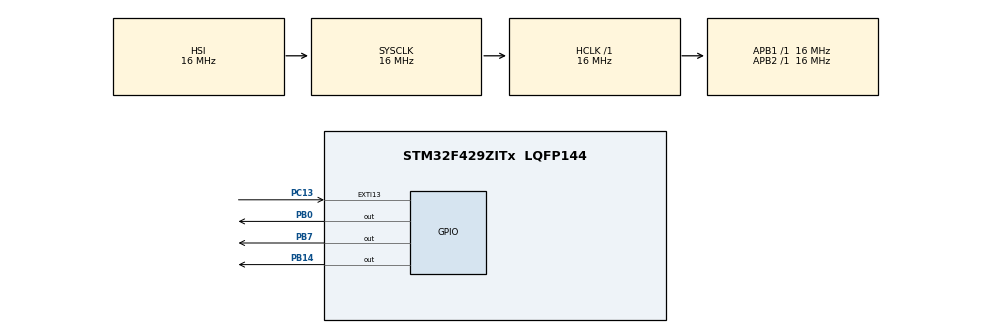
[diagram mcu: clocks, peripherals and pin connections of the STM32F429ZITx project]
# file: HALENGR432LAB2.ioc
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Mcu.Family=STM32F4
Mcu.Name=STM32F429ZITx
Mcu.Package=LQFP144
NVIC.EXTI15_10_IRQn=true\:0\:0\:false\:false\:true\:true\:true\:true
NVIC.PriorityGroup=NVIC_PRIORITYGROUP_4
NVIC.TIM2_IRQn=true\:0\:0\:false\:false\:true\:true\:true\:true
PB0.Signal=GPIO_Output
PB14.Signal=GPIO_Output
PB7.Signal=GPIO_Output
PC13.Signal=GPXTI13
ProjectManager.HeapSize=0x200
ProjectManager.StackSize=0x400
ProjectManager.TargetToolchain=MDK-ARM V5
RCC.AHBFreq_Value=16000000
RCC.APB1Freq_Value=16000000
RCC.APB2Freq_Value=16000000
RCC.CortexFreq_Value=16000000
RCC.HSE_VALUE=25000000
RCC.HSI_VALUE=16000000
RCC.LSE_VALUE=32768
RCC.SYSCLKFreq_VALUE=16000000
RCC.VCOOutputFreq_Value=192000000
TIM2.Period=21000
TIM2.Prescaler=999
VP_TIM2_VS_ClockSourceINT.Mode=Internal
board=custom

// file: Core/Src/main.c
/* USER CODE BEGIN Header */
/**
  ******************************************************************************
  * @file           : main.c
  * @brief          : Main program body
  ******************************************************************************
  * @attention
  *
  * Copyright (c) 2024 STMicroelectronics.
  * All rights reserved.
  *
  * This software is licensed under terms that can be found in the LICENSE file
  * in the root directory of this software component.
  * If no LICENSE file comes with this software, it is provided AS-IS.
  *
  ******************************************************************************
  */
/* USER CODE END Header */
#include "main.h"

/* USER CODE BEGIN PD */
int count = 0;

int Countup = 1;
int Downcount_Delay = 0;
int Bit0 = 0; // bit 1 2 & 3 for out binary counter
int Bit1 = 0; // you could say it's a BIT of a hacky solution
int Bit2 = 0; // yea ...
/* USER CODE END PD */

TIM_HandleTypeDef htim2;

void SystemClock_Config(void);
static void MX_GPIO_Init(void);
static void MX_TIM2_Init(void);

int main(void)
{

  /* MCU Configuration--------------------------------------------------------*/

  /* Reset of all peripherals, Initializes the Flash interface and the Systick. */
  HAL_Init();

  /* Configure the system clock */
  SystemClock_Config();

  /* Initialize all configured peripherals */
  MX_GPIO_Init();
  MX_TIM2_Init();
  /* USER CODE BEGIN 2 */

/*
void HAL_GPIO_EXTI_Callback()// callback for pushbutton
{

}
	*/

/* USER CODE END 2 */

  /* Infinite loop */
  while (1)
  {
while(1) {

	/*
HAL_GPIO_TogglePin(GPIOB, GPIO_PIN_0);
HAL_GPIO_TogglePin(GPIOB, GPIO_PIN_7);
HAL_GPIO_TogglePin(GPIOB, GPIO_PIN_14);

	HAL_GPIO_WritePin(GPIOB, GPIO_PIN_0, GPIO_PIN_RESET);
	HAL_Delay(1000);
	HAL_GPIO_WritePin(GPIOB, GPIO_PIN_0, GPIO_PIN_SET);
	HAL_Delay(1000);

	*/

	if((HAL_GPIO_ReadPin (GPIOC, GPIO_PIN_13) == 1))
	{
	Countup ^= 1u; // toggles counting
		Downcount_Delay = 0; // for consistiency
	}

	if((count == 7) && (Countup == 1)){
	count = 0;
	}
	else if((count == 0)&&(Countup == 0)&&(Downcount_Delay == 1)){
	count = 7;
	Downcount_Delay = 0;
	}
	else if((Countup == 0)&&(Downcount_Delay == 1)){
	count--;
	Downcount_Delay = 0;
	}
	else if((Countup == 1)){
	count++;
	}
	else{
		Downcount_Delay = 1;
	}
	Bit0 = count;
	Bit1 = count;
	Bit2 = count;

	// ez little bit mapping int >> binary, another note for future me, possible use another way ? research more efficient way

	Bit0 &= 1u; // NO actually and like: 001 &=> 111 = 001 etc, bit capture//////// XOR for st8 machine
	Bit1 &= 2u;
	Bit2 &= 4u;

	if(Bit0){
	HAL_GPIO_WritePin(GPIOB, GPIO_PIN_0, GPIO_PIN_SET);
	}
	else
	{
	HAL_GPIO_WritePin(GPIOB, GPIO_PIN_0, GPIO_PIN_RESET);
	}

	if(Bit1 == 2u){
	HAL_GPIO_WritePin(GPIOB, GPIO_PIN_7, GPIO_PIN_SET);
	}
	else
	{
	HAL_GPIO_WritePin(GPIOB, GPIO_PIN_7, GPIO_PIN_RESET);
	}

	if(Bit2 == 4u){
	HAL_GPIO_WritePin(GPIOB, GPIO_PIN_14, GPIO_PIN_SET);
	}
	else
	{
	HAL_GPIO_WritePin(GPIOB, GPIO_PIN_14, GPIO_PIN_RESET);
	}
	// R B G
	// M   L
	// 0 0 0
	// 0 0 1
	// 0 1 0
	// e t c
HAL_Delay(1000);
}

}
  }

void SystemClock_Config(void)
{
  RCC_OscInitTypeDef RCC_OscInitStruct = {0};
  RCC_ClkInitTypeDef RCC_ClkInitStruct = {0};

  /** Configure the main internal regulator output voltage
  */
  __HAL_RCC_PWR_CLK_ENABLE();
  __HAL_PWR_VOLTAGESCALING_CONFIG(PWR_REGULATOR_VOLTAGE_SCALE3);

  /** Initializes the RCC Oscillators according to the specified parameters
  * in the RCC_OscInitTypeDef structure.
  */
  RCC_OscInitStruct.OscillatorType = RCC_OSCILLATORTYPE_HSI;
  RCC_OscInitStruct.HSIState = RCC_HSI_ON;
  RCC_OscInitStruct.HSICalibrationValue = RCC_HSICALIBRATION_DEFAULT;
  RCC_OscInitStruct.PLL.PLLState = RCC_PLL_NONE;
  if (HAL_RCC_OscConfig(&RCC_OscInitStruct) != HAL_OK)
  {
    Error_Handler();
  }

  /** Initializes the CPU, AHB and APB buses clocks
  */
  RCC_ClkInitStruct.ClockType = RCC_CLOCKTYPE_HCLK|RCC_CLOCKTYPE_SYSCLK
                              |RCC_CLOCKTYPE_PCLK1|RCC_CLOCKTYPE_PCLK2;
  RCC_ClkInitStruct.SYSCLKSource = RCC_SYSCLKSOURCE_HSI;
  RCC_ClkInitStruct.AHBCLKDivider = RCC_SYSCLK_DIV1;
  RCC_ClkInitStruct.APB1CLKDivider = RCC_HCLK_DIV1;
  RCC_ClkInitStruct.APB2CLKDivider = RCC_HCLK_DIV1;

  if (HAL_RCC_ClockConfig(&RCC_ClkInitStruct, FLASH_LATENCY_0) != HAL_OK)
  {
    Error_Handler();
  }
}

static void MX_TIM2_Init(void)
{

  TIM_ClockConfigTypeDef sClockSourceConfig = {0};
  TIM_MasterConfigTypeDef sMasterConfig = {0};

  htim2.Instance = TIM2;
  htim2.Init.Prescaler = 999;
  htim2.Init.CounterMode = TIM_COUNTERMODE_UP;
  htim2.Init.Period = 21000;
  htim2.Init.ClockDivision = TIM_CLOCKDIVISION_DIV1;
  htim2.Init.AutoReloadPreload = TIM_AUTORELOAD_PRELOAD_DISABLE;
  if (HAL_TIM_Base_Init(&htim2) != HAL_OK)
  {
    Error_Handler();
  }
  sClockSourceConfig.ClockSource = TIM_CLOCKSOURCE_INTERNAL;
  if (HAL_TIM_ConfigClockSource(&htim2, &sClockSourceConfig) != HAL_OK)
  {
    Error_Handler();
  }
  sMasterConfig.MasterOutputTrigger = TIM_TRGO_RESET;
  sMasterConfig.MasterSlaveMode = TIM_MASTERSLAVEMODE_DISABLE;
  if (HAL_TIMEx_MasterConfigSynchronization(&htim2, &sMasterConfig) != HAL_OK)
  {
    Error_Handler();
  }

}

static void MX_GPIO_Init(void)
{
  GPIO_InitTypeDef GPIO_InitStruct = {0};

  /* GPIO Ports Clock Enable */
  __HAL_RCC_GPIOC_CLK_ENABLE();
  __HAL_RCC_GPIOB_CLK_ENABLE();

  /*Configure GPIO pin Output Level */
  HAL_GPIO_WritePin(GPIOB, GPIO_PIN_0|GPIO_PIN_14|GPIO_PIN_7, GPIO_PIN_RESET);

  /*Configure GPIO pin : PC13 */
  GPIO_InitStruct.Pin = GPIO_PIN_13;
  GPIO_InitStruct.Mode = GPIO_MODE_IT_RISING;
  GPIO_InitStruct.Pull = GPIO_NOPULL;
  HAL_GPIO_Init(GPIOC, &GPIO_InitStruct);

  /*Configure GPIO pins : PB0 PB14 PB7 */
  GPIO_InitStruct.Pin = GPIO_PIN_0|GPIO_PIN_14|GPIO_PIN_7;
  GPIO_InitStruct.Mode = GPIO_MODE_OUTPUT_PP;
  GPIO_InitStruct.Pull = GPIO_NOPULL;
  GPIO_InitStruct.Speed = GPIO_SPEED_FREQ_LOW;
  HAL_GPIO_Init(GPIOB, &GPIO_InitStruct);

  /* EXTI interrupt init*/
  HAL_NVIC_SetPriority(EXTI15_10_IRQn, 0, 0);
  HAL_NVIC_EnableIRQ(EXTI15_10_IRQn);

}

void Error_Handler(void)
{
  __disable_irq();
  while (1)
  {
  }
}
